# SC32F10T_10G register map
File version: 1.0
CPU: CM0+ r0p1, little endian, MPU, no FPU, 4 interrupt priority bits
Registers are 32-bit, read-write, reset 0x0 unless marked. A register's access mark holds for its fields unless they carry their own. Offsets are from the block's base; [hi:lo] are bit positions; 'fields as' and 'values as' point back to an identical list.

## SPI1
Base 0x40021040
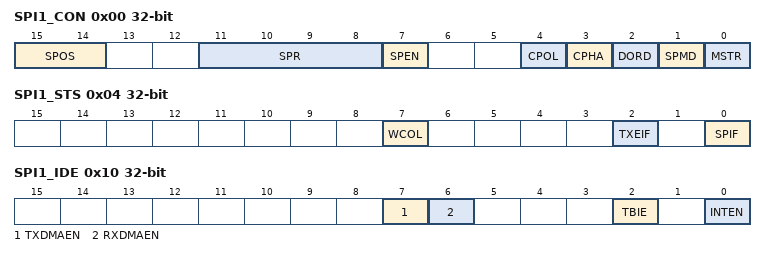
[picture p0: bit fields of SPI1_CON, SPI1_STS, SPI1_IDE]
0x00 SPI1_CON — SPI控制寄存器
  [15:14] SPOS — SPI信号口映射控制位信号SPOS值MISO1MOSI1SCK1SPOS[1:0]=00PA14PA13PA12SPOS[1:0]=01PA4PA5PA6
  [11:8] SPR — SPI时钟预分频控制位0000：fPCLK10001：fPCLK1 /20010：fPCLK1 /40011：fPCLK1 /80100：fPCLK1 /160101：fPCLK1 /320110：fPCLK1 /640111：fPCLK1 /1281000：fPCLK1 /2561001：fPCLK1 /5121010：fPCLK1 /1024其它：fPCLK1 /1024
  [7] SPEN — SPI使能控制位0：关闭SPI11：打开SPI1
  [4] CPOL — SPI时钟极性控制位0：SCK在空闲状态下为低电平1：SCK在空闲状态下为高电平
  [3] CPHA — SPI时钟相位控制位0：SCK周期的第一沿采集数据1：SCK周期的第二沿采集数据
  [2] DORD — SPI传送方向选择位0：MSB优先发送1：LSB优先发送
  [1] SPMD — SPI传输模式选择位0：8位模式1：16位模式
  [0] MSTR — SPI主从机模式选择位0：SPI1为从设备1：SPI1为主设备
0x04 SPI1_STS — SPI标志位寄存器
  [7] WCOL — 写入冲突标志位该位由硬件置1，通过软件写1清0，用于指示是否发生写入冲突：0：未检测到写入冲突1：检测到一个写入冲突
  [2] TXEIF — 发送缓存为空标志位用于指示当前发送缓存是否为空：0：发送缓存非空1：发送缓存为空该位由硬件置1，通过软件写1清0。注意：在DMA模式下，DMA写入发送缓存后，该位由DMA模块清0，此时用户无需通过软件清0。
  [0] SPIF — SPI数据传送标志位该位由硬件置1，通过软件写1清0，用于指示当前SPI数据传输是否完成：0：数据传输未完成/进行中1：数据传输已完成
0x0C SPI1_DATA — SPI数据寄存器
  [15:0] SPD — SPI数据缓存读操作：从SPI1接收缓存读取接收到的数据写操作：向SPI1发送缓存写入待发送的数据
0x10 SPI1_IDE — 通信口DMA控制寄存器
  [7] TXDMAEN — DMA发送通道使能位0：禁用DMA发送功能1：使能DMA发送功能该位使能后，TXEIF置起可触发DMA通道发送请求
  [6] RXDMAEN — DMA接收通道使能位0：禁用DMA接收功能1：使能DMA接收功能该位使能后，SPIF置起可触发DMA通道接收请求
  [2] TBIE — 发送缓存为空时的中断使能位0：TXEIF置起时，不允许产生中断1：TXEIF置起时，产生中断
  [0] INTEN — 中断请求 CPU的使能控制位0：禁止中断请求1：使能中断请求

## TWI0
Base 0x40020060
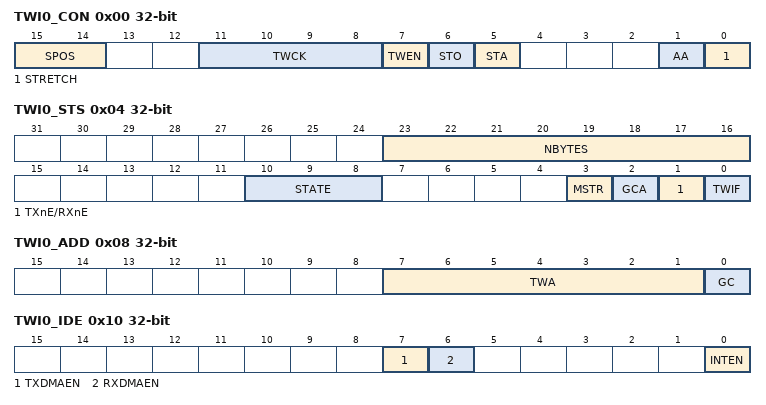
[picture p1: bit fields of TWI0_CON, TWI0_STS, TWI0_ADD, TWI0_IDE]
0x00 TWI0_CON — TWI控制寄存器
  [15:14] SPOS — TWI0信号口映射控制位@TWI0_CON 信号SPOS值SCL0SDA0SPOS[1:0]=00PB1PB0SPOS[1:0]=01PC10PC11SPOS[1:0]=10PA6PA5SPOS[1:0]=11PA13PA14TWI1信号口映射控制位@TWI1_CON
  [11:8] TWCK — 主机模式下TWI的通信速率设定：0000：fPCLK /4096 0001：fPCLK /20480010：fPCLK /10240011：fPCLK /5120100：fPCLK /2560101：fPCLK /1280110：fPCLK /640111：fPCLK /321000：fPCLK /161001：fPCLK /81010：fPCLK /4其它：fPCLK /4TWI0的通信速率fT
  [7] TWEN — TWI使能控制位0：关闭TWI1：打开TWI
  [6] STO — TWI停止位触发开关主机模式下，对该位写1，在当前字节传输或起始条件发出后产生停止条件。软件可以设置或清除该位，或当检测到停止条件时，由硬件清除。
  [5] STA — TWI起始位触发开关该位写1将产生起始条件，TWI将切换为主机模式。软件可以设置或清除该位，或当起始条件发出后，由硬件清0。
  [1] AA — TWI应答使能位0：无应答，返回UACK（应答位为高电平）1：在接收到一个匹配的地址或数据后返回一个应答ACK
  [0] STRETCH — TWI时钟延长使能位该位仅在从机模式下有效0：禁止时钟延长1：允许时钟延长，主机需要支持时钟延长功能说明：在数据传输完成之后，且ACK为0，此时时钟延长发生。
0x04 TWI0_STS — TWI标志位寄存器
  [23:16] NBYTES — 收发缓存字节数设置位用于设置待发送/接收的字节数。每发送/接收成功一个自己NBYTES自动减1，当NBYTES为0时TC标志位将置起。注意：STA置1时不允许修改。
  [10:8] STATE — TWI状态位用于指示TWI状态，主/从机模式下状态位含义不同。从机模式：000：从机处于空闲状态，等待TWEN置1，检测TWI 启动信号。当从机接收到停止条件后跳转到此状态001：从机正在接收第一帧地址和读写位（第8位为读写位，1为读，0为写）。从机接收到起始条件后会跳转到此状态010：从机接收数据状态011：从机发送数据状态100：在从机发送数据状态中，当主机回UACK时跳转到此状态，等待重新启
  [3] MSTR — TWI主/从机模式标志位0：从机模式1：主机模式说明：当TWI接口向总线发出起始条件后，会自动切换为主机模式，同时硬件将该位置位；当总线上检测到一个停止条件时，硬件清除该位。
  [2] GCA — TWI通用地址响应标志位0：非响应通用地址1：当GC置1，同时通用地址匹配时该位由硬件置1，并自动清0
  [1] TXnE/RXnE — TWI传输完成标志位以下情况，TXnE/RXnE由硬件置1主机模式：主机发送地址帧（写），且收到从机的ACK主机发送完数据，且接收到从机ACK主机接收到数据，且主机回从机ACK从机模式：从机接收地址帧（读），且和从机地址（TWA）匹配从机接收到数据，且从机回主机ACK从机发送完数据，且接收到主机ACK（AA=1）对TWIDAT进行读写操作后，该位将被硬件清除。
  [0] TWIF — TWI中断标志位该位由硬件置1，通过软件写1清0。主机模式：发送启动信号发送完地址帧接收或发送完数据帧从机模式：第一帧地址匹配成功成功接收或发送8位数据接收到重复起始条件从机收到停止信号
0x08 TWI0_ADD — TWI地址寄存器
  [7:1] TWA — TWI地址寄存器TWA[6:0]不能写为全0，00H为通用地址寻址专用。该位在主机模式下无效。
  [0] GC — TWI通用地址响应使能位 0： 禁止响应通用地址00H 1： 允许响应通用地址00H
0x0C TWI0_DATA — TWI数据寄存器
  [7:0] TWIDAT — TWI数据缓存读操作：从TWI接收缓存读取接收到的数据写操作：向TWI发送缓存写入待发送的数据
0x10 TWI0_IDE — 通信口DMA控制寄存器
  [7] TXDMAEN — DMA发送通道使能位0：禁用DMA发送功能1：使能DMA发送功能该位使能后，TXnE/RXnE置起可触发DMA通道发送请求注意：TWI0可产生DMA请求TWI1不能产生DMA请求
  [6] RXDMAEN — DMA接收通道使能位0：禁用DMA接收功能1：使能DMA接收功能该位使能后，TXnE/RXnE置起可触发DMA通道接收请求注意：TWI0可产生DMA请求TWI1不能产生DMA请求
  [0] INTEN — 中断请求 CPU的使能控制位0：禁止中断请求1：使能中断请求

## TWI1
Base 0x40021060
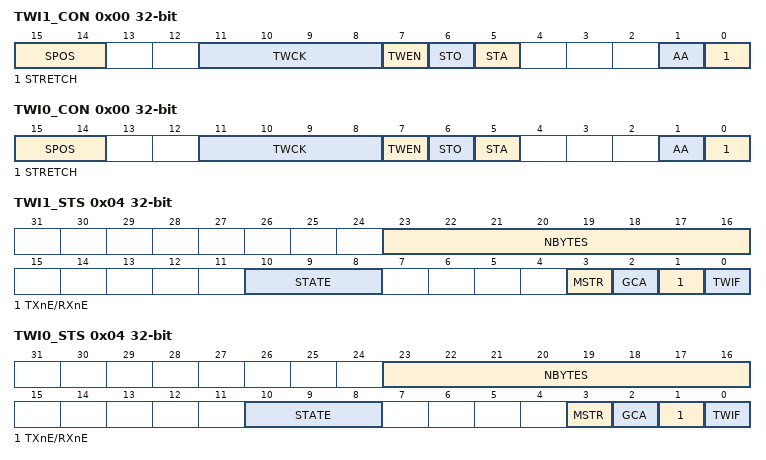
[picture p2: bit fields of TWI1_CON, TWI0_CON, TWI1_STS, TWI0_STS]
0x00 TWI1_CON — TWI控制寄存器
  [15:14] SPOS — TWI0信号口映射控制位@TWI0_CON 信号SPOS值SCL0SDA0SPOS[1:0]=00PB1PB0SPOS[1:0]=01PC10PC11SPOS[1:0]=10PA6PA5SPOS[1:0]=11PA13PA14TWI1信号口映射控制位@TWI1_CON
  [11:8] TWCK — 主机模式下TWI的通信速率设定：0000：fPCLK /4096 0001：fPCLK /20480010：fPCLK /10240011：fPCLK /5120100：fPCLK /2560101：fPCLK /1280110：fPCLK /640111：fPCLK /321000：fPCLK /161001：fPCLK /81010：fPCLK /4其它：fPCLK /4TWI0的通信速率fT
  [7] TWEN — TWI使能控制位0：关闭TWI1：打开TWI
  [6] STO — TWI停止位触发开关主机模式下，对该位写1，在当前字节传输或起始条件发出后产生停止条件。软件可以设置或清除该位，或当检测到停止条件时，由硬件清除。
  [5] STA — TWI起始位触发开关该位写1将产生起始条件，TWI将切换为主机模式。软件可以设置或清除该位，或当起始条件发出后，由硬件清0。
  [1] AA — TWI应答使能位0：无应答，返回UACK（应答位为高电平）1：在接收到一个匹配的地址或数据后返回一个应答ACK
  [0] STRETCH — TWI时钟延长使能位该位仅在从机模式下有效0：禁止时钟延长1：允许时钟延长，主机需要支持时钟延长功能说明：在数据传输完成之后，且ACK为0，此时时钟延长发生。
0x00 TWI0_CON — TWI控制寄存器
  fields as TWI1_CON
0x04 TWI1_STS — TWI标志位寄存器
  [23:16] NBYTES — 收发缓存字节数设置位用于设置待发送/接收的字节数。每发送/接收成功一个自己NBYTES自动减1，当NBYTES为0时TC标志位将置起。注意：STA置1时不允许修改。
  [10:8] STATE — TWI状态位用于指示TWI状态，主/从机模式下状态位含义不同。从机模式：000：从机处于空闲状态，等待TWEN置1，检测TWI 启动信号。当从机接收到停止条件后跳转到此状态001：从机正在接收第一帧地址和读写位（第8位为读写位，1为读，0为写）。从机接收到起始条件后会跳转到此状态010：从机接收数据状态011：从机发送数据状态100：在从机发送数据状态中，当主机回UACK时跳转到此状态，等待重新启
  [3] MSTR — TWI主/从机模式标志位0：从机模式1：主机模式说明：当TWI接口向总线发出起始条件后，会自动切换为主机模式，同时硬件将该位置位；当总线上检测到一个停止条件时，硬件清除该位。
  [2] GCA — TWI通用地址响应标志位0：非响应通用地址1：当GC置1，同时通用地址匹配时该位由硬件置1，并自动清0
  [1] TXnE/RXnE — TWI传输完成标志位以下情况，TXnE/RXnE由硬件置1主机模式：主机发送地址帧（写），且收到从机的ACK主机发送完数据，且接收到从机ACK主机接收到数据，且主机回从机ACK从机模式：从机接收地址帧（读），且和从机地址（TWA）匹配从机接收到数据，且从机回主机ACK从机发送完数据，且接收到主机ACK（AA=1）对TWIDAT进行读写操作后，该位将被硬件清除。
  [0] TWIF — TWI中断标志位该位由硬件置1，通过软件写1清0。主机模式：发送启动信号发送完地址帧接收或发送完数据帧从机模式：第一帧地址匹配成功成功接收或发送8位数据接收到重复起始条件从机收到停止信号
0x04 TWI0_STS — TWI标志位寄存器
  fields as TWI1_STS
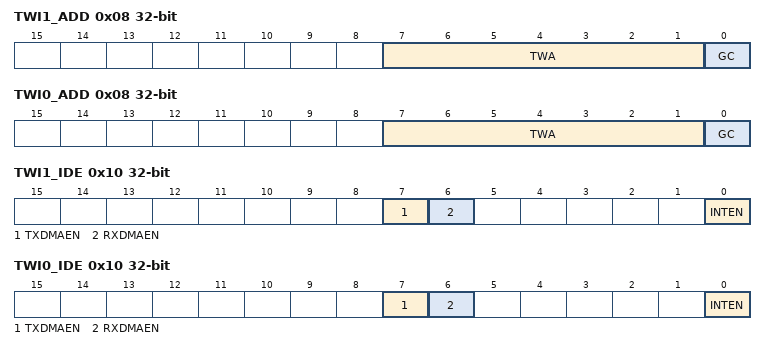
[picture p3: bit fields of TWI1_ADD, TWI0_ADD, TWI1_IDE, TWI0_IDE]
0x08 TWI1_ADD — TWI地址寄存器
  [7:1] TWA — TWI地址寄存器TWA[6:0]不能写为全0，00H为通用地址寻址专用。该位在主机模式下无效。
  [0] GC — TWI通用地址响应使能位 0： 禁止响应通用地址00H 1： 允许响应通用地址00H
0x08 TWI0_ADD — TWI地址寄存器
  fields as TWI1_ADD
0x0C TWI1_DATA — TWI数据寄存器
  [7:0] TWIDAT — TWI数据缓存读操作：从TWI接收缓存读取接收到的数据写操作：向TWI发送缓存写入待发送的数据
0x0C TWI0_DATA — TWI数据寄存器
  [7:0] TWIDAT — TWI数据缓存读操作：从TWI接收缓存读取接收到的数据写操作：向TWI发送缓存写入待发送的数据
0x10 TWI1_IDE — 通信口DMA控制寄存器
  [7] TXDMAEN — DMA发送通道使能位0：禁用DMA发送功能1：使能DMA发送功能该位使能后，TXnE/RXnE置起可触发DMA通道发送请求注意：TWI0可产生DMA请求TWI1不能产生DMA请求
  [6] RXDMAEN — DMA接收通道使能位0：禁用DMA接收功能1：使能DMA接收功能该位使能后，TXnE/RXnE置起可触发DMA通道接收请求注意：TWI0可产生DMA请求TWI1不能产生DMA请求
  [0] INTEN — 中断请求 CPU的使能控制位0：禁止中断请求1：使能中断请求
0x10 TWI0_IDE — 通信口DMA控制寄存器
  fields as TWI1_IDE
